# RP2040 register map
Vendor: Raspberry Pi; File version: 2025.06.15
CPU: CM0PLUS r0p1, little endian, 2 interrupt priority bits
Registers are 32-bit, read-write, no defined reset value unless marked. A register's access mark holds for its fields unless they carry their own. Offsets are from the block's base; [hi:lo] are bit positions.

## SPI0
Base 0x4003C000
Same registers: SPI1 0x40040000
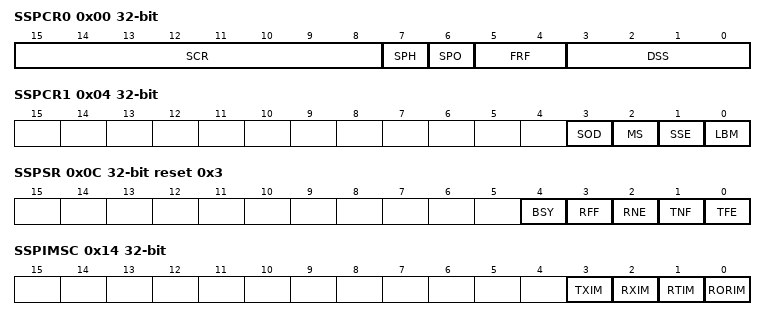
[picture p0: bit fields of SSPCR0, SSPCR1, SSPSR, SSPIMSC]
0x00 SSPCR0 — Control register 0, SSPCR0 on page 3-4
  [15:8] SCR — Serial clock rate. The value SCR is used to generate the transmit and receive bit rate of the PrimeCell SSP. The bit rate is: F SSPCLK CPSDVSR x (1+SCR) where CPSDVSR is an even value from 2-254, programmed through the SSPCPSR register and SCR is a value from 0-255.
  [7] SPH — SSPCLKOUT phase, applicable to Motorola SPI frame format only. See Motorola SPI frame format on page 2-10.
  [6] SPO — SSPCLKOUT polarity, applicable to Motorola SPI frame format only. See Motorola SPI frame format on page 2-10.
  [5:4] FRF — Frame format: 00 Motorola SPI frame format. 01 TI synchronous serial frame format. 10 National Microwire frame format. 11 Reserved, undefined operation.
  [3:0] DSS — Data Size Select: 0000 Reserved, undefined operation. 0001 Reserved, undefined operation. 0010 Reserved, undefined operation. 0011 4-bit data. 0100 5-bit data. 0101 6-bit data. 0110 7-bit data. 0111 8-bit data. 1000 9-bit data. 1001 10-bit data. 1010 11-bit data. 1011 12-bit data. 1100 13-bit data. 1101 14-bit data. 1110 15-bit data. 1111 16-bit data.
0x04 SSPCR1 — Control register 1, SSPCR1 on page 3-5
  [3] SOD — Slave-mode output disable. This bit is relevant only in the slave mode, MS=1. In multiple-slave systems, it is possible for an PrimeCell SSP master to broadcast a message to all slaves in the system while ensuring that only one slave drives data onto its serial output line. In such systems the RXD lines from multiple slaves could be tied together. To operate in such systems, the SOD bit can be set if the PrimeCell SSP slave is not supposed to drive the SSPTXD line: 0 SSP can drive the SSPTXD output in slave mode. 1 SSP must not drive the SSPTXD output in slave mode.
  [2] MS — Master or slave mode select. This bit can be modified only when the PrimeCell SSP is disabled, SSE=0: 0 Device configured as master, default. 1 Device configured as slave.
  [1] SSE — Synchronous serial port enable: 0 SSP operation disabled. 1 SSP operation enabled.
  [0] LBM — Loop back mode: 0 Normal serial port operation enabled. 1 Output of transmit serial shifter is connected to input of receive serial shifter internally.
0x08 SSPDR — Data register, SSPDR on page 3-6
  [15:0] DATA — Transmit/Receive FIFO: Read Receive FIFO. Write Transmit FIFO. You must right-justify data when the PrimeCell SSP is programmed for a data size that is less than 16 bits. Unused bits at the top are ignored by transmit logic. The receive logic automatically right-justifies.
0x0C SSPSR reset 0x3 (reset mask 0x0) — Status register, SSPSR on page 3-7
  [4] BSY ro — PrimeCell SSP busy flag, RO: 0 SSP is idle. 1 SSP is currently transmitting and/or receiving a frame or the transmit FIFO is not empty.
  [3] RFF ro — Receive FIFO full, RO: 0 Receive FIFO is not full. 1 Receive FIFO is full.
  [2] RNE ro — Receive FIFO not empty, RO: 0 Receive FIFO is empty. 1 Receive FIFO is not empty.
  [1] TNF ro — Transmit FIFO not full, RO: 0 Transmit FIFO is full. 1 Transmit FIFO is not full.
  [0] TFE ro — Transmit FIFO empty, RO: 0 Transmit FIFO is not empty. 1 Transmit FIFO is empty.
0x10 SSPCPSR — Clock prescale register, SSPCPSR on page 3-8
  [7:0] CPSDVSR — Clock prescale divisor. Must be an even number from 2-254, depending on the frequency of SSPCLK. The least significant bit always returns zero on reads.
0x14 SSPIMSC — Interrupt mask set or clear register, SSPIMSC on page 3-9
  [3] TXIM — Transmit FIFO interrupt mask: 0 Transmit FIFO half empty or less condition interrupt is masked. 1 Transmit FIFO half empty or less condition interrupt is not masked.
  [2] RXIM — Receive FIFO interrupt mask: 0 Receive FIFO half full or less condition interrupt is masked. 1 Receive FIFO half full or less condition interrupt is not masked.
  [1] RTIM — Receive timeout interrupt mask: 0 Receive FIFO not empty and no read prior to timeout period interrupt is masked. 1 Receive FIFO not empty and no read prior to timeout period interrupt is not masked.
  [0] RORIM — Receive overrun interrupt mask: 0 Receive FIFO written to while full condition interrupt is masked. 1 Receive FIFO written to while full condition interrupt is not masked.
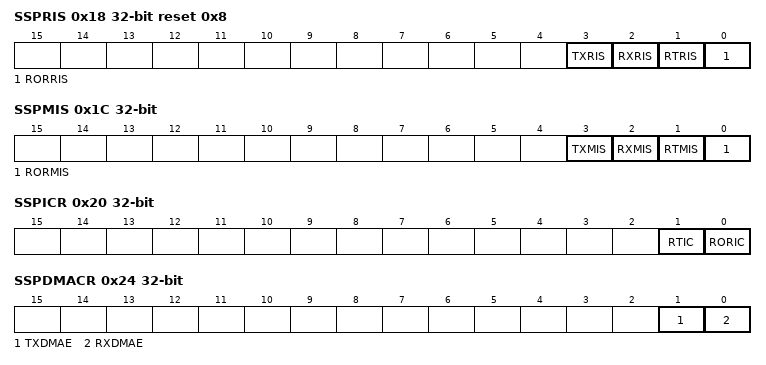
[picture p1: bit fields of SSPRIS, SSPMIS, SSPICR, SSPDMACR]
0x18 SSPRIS reset 0x8 (reset mask 0x0) — Raw interrupt status register, SSPRIS on page 3-10
  [3] TXRIS ro — Gives the raw interrupt state, prior to masking, of the SSPTXINTR interrupt
  [2] RXRIS ro — Gives the raw interrupt state, prior to masking, of the SSPRXINTR interrupt
  [1] RTRIS ro — Gives the raw interrupt state, prior to masking, of the SSPRTINTR interrupt
  [0] RORRIS ro — Gives the raw interrupt state, prior to masking, of the SSPRORINTR interrupt
0x1C SSPMIS — Masked interrupt status register, SSPMIS on page 3-11
  [3] TXMIS ro — Gives the transmit FIFO masked interrupt state, after masking, of the SSPTXINTR interrupt
  [2] RXMIS ro — Gives the receive FIFO masked interrupt state, after masking, of the SSPRXINTR interrupt
  [1] RTMIS ro — Gives the receive timeout masked interrupt state, after masking, of the SSPRTINTR interrupt
  [0] RORMIS ro — Gives the receive over run masked interrupt status, after masking, of the SSPRORINTR interrupt
0x20 SSPICR — Interrupt clear register, SSPICR on page 3-11
  [1] RTIC write-1-clears — Clears the SSPRTINTR interrupt
  [0] RORIC write-1-clears — Clears the SSPRORINTR interrupt
0x24 SSPDMACR — DMA control register, SSPDMACR on page 3-12
  [1] TXDMAE — Transmit DMA Enable. If this bit is set to 1, DMA for the transmit FIFO is enabled.
  [0] RXDMAE — Receive DMA Enable. If this bit is set to 1, DMA for the receive FIFO is enabled.
0xFE0 SSPPERIPHID0 reset 0x22 (reset mask 0x0) — Peripheral identification registers, SSPPeriphID0-3 on page 3-13
  [7:0] PARTNUMBER0 ro — These bits read back as 0x22
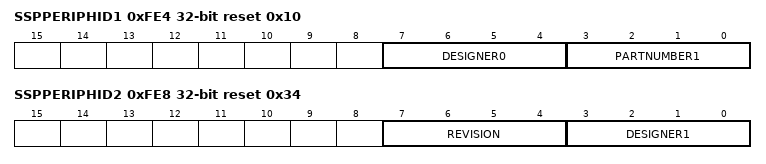
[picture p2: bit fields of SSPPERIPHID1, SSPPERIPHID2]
0xFE4 SSPPERIPHID1 reset 0x10 (reset mask 0x0) — Peripheral identification registers, SSPPeriphID0-3 on page 3-13
  [7:4] DESIGNER0 ro — These bits read back as 0x1
  [3:0] PARTNUMBER1 ro — These bits read back as 0x0
0xFE8 SSPPERIPHID2 reset 0x34 (reset mask 0x0) — Peripheral identification registers, SSPPeriphID0-3 on page 3-13
  [7:4] REVISION ro — These bits return the peripheral revision
  [3:0] DESIGNER1 ro — These bits read back as 0x4
0xFEC SSPPERIPHID3 — Peripheral identification registers, SSPPeriphID0-3 on page 3-13
  [7:0] CONFIGURATION ro — These bits read back as 0x00
0xFF0 SSPPCELLID0 reset 0xD (reset mask 0x0) — PrimeCell identification registers, SSPPCellID0-3 on page 3-16
  [7:0] SSPPCELLID0 ro — These bits read back as 0x0D
0xFF4 SSPPCELLID1 reset 0xF0 (reset mask 0x0) — PrimeCell identification registers, SSPPCellID0-3 on page 3-16
  [7:0] SSPPCELLID1 ro — These bits read back as 0xF0
0xFF8 SSPPCELLID2 reset 0x5 (reset mask 0x0) — PrimeCell identification registers, SSPPCellID0-3 on page 3-16
  [7:0] SSPPCELLID2 ro — These bits read back as 0x05
0xFFC SSPPCELLID3 reset 0xB1 (reset mask 0x0) — PrimeCell identification registers, SSPPCellID0-3 on page 3-16
  [7:0] SSPPCELLID3 ro — These bits read back as 0xB1
